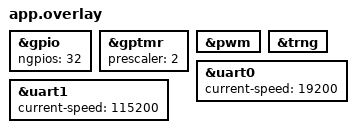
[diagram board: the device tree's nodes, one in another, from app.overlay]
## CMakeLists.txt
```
# SPDX-License-Identifier: Apache-2.0
#
# Copyright (c) 2025 Henrik Brix Andersen <henrik@brixandersen.dk>

cmake_minimum_required(VERSION 3.28.0)

find_package(Zephyr REQUIRED HINTS $ENV{ZEPHYR_BASE})
project(build_all_neorv32)

FILE(GLOB app_sources src/*.c)
target_sources(app PRIVATE ${app_sources})
```

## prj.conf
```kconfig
CONFIG_TEST=y
CONFIG_TEST_USERSPACE=y

CONFIG_COUNTER=y
CONFIG_GPIO=y
CONFIG_ENTROPY_GENERATOR=y
CONFIG_PWM=y

CONFIG_SERIAL=y
CONFIG_UART_INTERRUPT_DRIVEN=y
CONFIG_UART_USE_RUNTIME_CONFIGURE=y
```

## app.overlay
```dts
/*
 * Copyright (c) 2025 Henrik Brix Andersen <henrik@brixandersen.dk>
 *
 * SPDX-License-Identifier: Apache-2.0
 */

&gpio {
	ngpios = <32>;
	status = "okay";
};

&gptmr {
	prescaler = <2>;
	status = "okay";
};

&pwm {
	status = "okay";
};

&trng {
	status = "okay";
};

&uart0 {
	current-speed = <19200>;
	status = "okay";
};

&uart1 {
	current-speed = <115200>;
	status = "okay";
};
```

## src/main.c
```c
/*
 * Copyright (c) 2025 Henrik Brix Andersen <henrik@brixandersen.dk>
 *
 * SPDX-License-Identifier: Apache-2.0
 */

int main(void)
{
	return 0;
}
```
